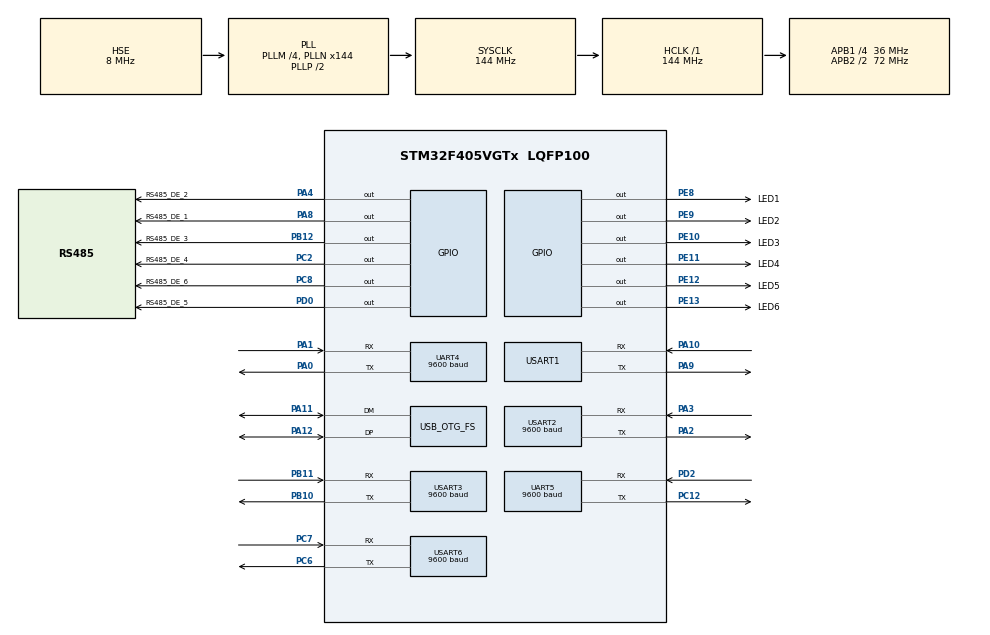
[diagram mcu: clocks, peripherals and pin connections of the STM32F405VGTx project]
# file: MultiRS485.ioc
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Dma.Request0=USART6_RX
Dma.Request1=USART3_RX
Dma.Request2=UART4_RX
Dma.Request3=UART5_RX
Dma.Request4=USART1_RX
Dma.UART4_RX.2.Direction=DMA_PERIPH_TO_MEMORY
Dma.UART4_RX.2.FIFOMode=DMA_FIFOMODE_DISABLE
Dma.UART4_RX.2.Instance=DMA1_Stream2
Dma.UART4_RX.2.MemDataAlignment=DMA_MDATAALIGN_BYTE
Dma.UART4_RX.2.MemInc=DMA_MINC_ENABLE
Dma.UART4_RX.2.Mode=DMA_NORMAL
Dma.UART4_RX.2.PeriphDataAlignment=DMA_PDATAALIGN_BYTE
Dma.UART4_RX.2.PeriphInc=DMA_PINC_DISABLE
Dma.UART4_RX.2.Priority=DMA_PRIORITY_LOW
Dma.UART5_RX.3.Direction=DMA_PERIPH_TO_MEMORY
Dma.UART5_RX.3.FIFOMode=DMA_FIFOMODE_DISABLE
Dma.UART5_RX.3.Instance=DMA1_Stream0
Dma.UART5_RX.3.MemDataAlignment=DMA_MDATAALIGN_BYTE
Dma.UART5_RX.3.MemInc=DMA_MINC_ENABLE
Dma.UART5_RX.3.Mode=DMA_NORMAL
Dma.UART5_RX.3.PeriphDataAlignment=DMA_PDATAALIGN_BYTE
Dma.UART5_RX.3.PeriphInc=DMA_PINC_DISABLE
Dma.UART5_RX.3.Priority=DMA_PRIORITY_LOW
Dma.USART1_RX.4.Direction=DMA_PERIPH_TO_MEMORY
Dma.USART1_RX.4.FIFOMode=DMA_FIFOMODE_DISABLE
Dma.USART1_RX.4.Instance=DMA2_Stream2
Dma.USART1_RX.4.MemDataAlignment=DMA_MDATAALIGN_BYTE
Dma.USART1_RX.4.MemInc=DMA_MINC_ENABLE
Dma.USART1_RX.4.Mode=DMA_NORMAL
Dma.USART1_RX.4.PeriphDataAlignment=DMA_PDATAALIGN_BYTE
Dma.USART1_RX.4.PeriphInc=DMA_PINC_DISABLE
Dma.USART1_RX.4.Priority=DMA_PRIORITY_LOW
Dma.USART3_RX.1.Direction=DMA_PERIPH_TO_MEMORY
Dma.USART3_RX.1.FIFOMode=DMA_FIFOMODE_DISABLE
Dma.USART3_RX.1.Instance=DMA1_Stream1
Dma.USART3_RX.1.MemDataAlignment=DMA_MDATAALIGN_BYTE
Dma.USART3_RX.1.MemInc=DMA_MINC_ENABLE
Dma.USART3_RX.1.Mode=DMA_NORMAL
Dma.USART3_RX.1.PeriphDataAlignment=DMA_PDATAALIGN_BYTE
Dma.USART3_RX.1.PeriphInc=DMA_PINC_DISABLE
Dma.USART3_RX.1.Priority=DMA_PRIORITY_LOW
Dma.USART6_RX.0.Direction=DMA_PERIPH_TO_MEMORY
Dma.USART6_RX.0.FIFOMode=DMA_FIFOMODE_DISABLE
Dma.USART6_RX.0.Instance=DMA2_Stream1
Dma.USART6_RX.0.MemDataAlignment=DMA_MDATAALIGN_BYTE
Dma.USART6_RX.0.MemInc=DMA_MINC_ENABLE
Dma.USART6_RX.0.Mode=DMA_NORMAL
Dma.USART6_RX.0.PeriphDataAlignment=DMA_PDATAALIGN_BYTE
Dma.USART6_RX.0.PeriphInc=DMA_PINC_DISABLE
Dma.USART6_RX.0.Priority=DMA_PRIORITY_LOW
FREERTOS.Tasks01=defaultTask,0,128,StartDefaultTask,Default,NULL
Mcu.Family=STM32F4
Mcu.Name=STM32F405VGTx
Mcu.Package=LQFP100
NVIC.DMA1_Stream0_IRQn=true\:5\:0\:false\:false\:true\:true\:false
NVIC.DMA1_Stream1_IRQn=true\:5\:0\:false\:false\:true\:true\:false
NVIC.DMA1_Stream2_IRQn=true\:5\:0\:false\:false\:true\:true\:false
NVIC.DMA2_Stream1_IRQn=true\:5\:0\:false\:false\:true\:true\:false
NVIC.DMA2_Stream2_IRQn=true\:5\:0\:false\:false\:true\:true\:false
NVIC.OTG_FS_IRQn=true\:5\:0\:false\:false\:true\:true\:false
NVIC.PriorityGroup=NVIC_PRIORITYGROUP_4
NVIC.TIM6_DAC_IRQn=true\:0\:0\:false\:false\:true\:false\:false
NVIC.TIM7_IRQn=true\:5\:0\:false\:false\:true\:true\:true
NVIC.TimeBase=TIM6_DAC_IRQn
NVIC.TimeBaseIP=TIM6
NVIC.UART4_IRQn=true\:5\:0\:false\:false\:true\:true\:true
NVIC.UART5_IRQn=true\:5\:0\:false\:false\:true\:true\:true
NVIC.USART1_IRQn=true\:5\:0\:false\:false\:true\:true\:true
NVIC.USART2_IRQn=true\:5\:0\:false\:false\:true\:true\:true
NVIC.USART3_IRQn=true\:5\:0\:false\:false\:true\:true\:true
NVIC.USART6_IRQn=true\:5\:0\:false\:false\:true\:true\:true
PA0-WKUP.Mode=Asynchronous
PA0-WKUP.Signal=UART4_TX
PA1.Mode=Asynchronous
PA1.Signal=UART4_RX
PA10.Mode=Asynchronous
PA10.Signal=USART1_RX
PA11.Mode=Device_Only
PA11.Signal=USB_OTG_FS_DM
PA12.Mode=Device_Only
PA12.Signal=USB_OTG_FS_DP
PA13.Mode=Serial_Wire
PA13.Signal=SYS_JTMS-SWDIO
PA14.Mode=Serial_Wire
PA14.Signal=SYS_JTCK-SWCLK
PA2.Mode=Asynchronous
PA2.Signal=USART2_TX
PA3.Mode=Asynchronous
PA3.Signal=USART2_RX
PA4.GPIO_Label=RS485_DE_2
PA4.GPIO_PuPd=GPIO_PULLDOWN
PA4.Signal=GPIO_Output
PA8.GPIO_Label=RS485_DE_1
PA8.GPIO_PuPd=GPIO_PULLDOWN
PA8.Signal=GPIO_Output
PA9.Mode=Asynchronous
PA9.Signal=USART1_TX
PB10.Mode=Asynchronous
PB10.Signal=USART3_TX
PB11.Mode=Asynchronous
PB11.Signal=USART3_RX
PB12.GPIO_Label=RS485_DE_3
PB12.GPIO_PuPd=GPIO_PULLDOWN
PB12.Signal=GPIO_Output
PC12.Mode=Asynchronous
PC12.Signal=UART5_TX
PC2.GPIO_Label=RS485_DE_4
PC2.GPIO_PuPd=GPIO_PULLDOWN
PC2.Signal=GPIO_Output
PC6.Mode=Asynchronous
PC6.Signal=USART6_TX
PC7.Mode=Asynchronous
PC7.Signal=USART6_RX
PC8.GPIO_Label=RS485_DE_6
PC8.GPIO_PuPd=GPIO_PULLDOWN
PC8.Signal=GPIO_Output
PD0.GPIO_Label=RS485_DE_5
PD0.Signal=GPIO_Output
PD2.Mode=Asynchronous
PD2.Signal=UART5_RX
PE10.GPIO_Label=LED3
PE10.GPIO_PuPd=GPIO_PULLUP
PE10.Signal=GPIO_Output
PE11.GPIO_Label=LED4
PE11.GPIO_PuPd=GPIO_PULLUP
PE11.Signal=GPIO_Output
PE12.GPIO_Label=LED5
PE12.GPIO_PuPd=GPIO_PULLUP
PE12.Signal=GPIO_Output
PE13.GPIO_Label=LED6
PE13.GPIO_PuPd=GPIO_PULLUP
PE13.Signal=GPIO_Output
PE8.GPIO_Label=LED1
PE8.GPIO_PuPd=GPIO_PULLUP
PE8.Signal=GPIO_Output
PE9.GPIO_Label=LED2
PE9.GPIO_PuPd=GPIO_PULLUP
PE9.Signal=GPIO_Output
PH0-OSC_IN.Mode=HSE-External-Oscillator
PH0-OSC_IN.Signal=RCC_OSC_IN
PH1-OSC_OUT.Mode=HSE-External-Oscillator
PH1-OSC_OUT.Signal=RCC_OSC_OUT
ProjectManager.HeapSize=0x200
ProjectManager.StackSize=0x400
ProjectManager.TargetToolchain=MDK-ARM V5
RCC.48MHZClocksFreq_Value=48000000
RCC.AHBFreq_Value=144000000
RCC.APB1CLKDivider=RCC_HCLK_DIV4
RCC.APB1Freq_Value=36000000
RCC.APB1TimFreq_Value=72000000
RCC.APB2CLKDivider=RCC_HCLK_DIV2
RCC.APB2Freq_Value=72000000
RCC.APB2TimFreq_Value=144000000
RCC.CortexFreq_Value=144000000
RCC.HCLKFreq_Value=144000000
RCC.HSE_VALUE=8000000
RCC.HSI_VALUE=16000000
RCC.LSE_VALUE=32768
RCC.PLLM=4
RCC.PLLN=144
RCC.PLLQ=6
RCC.SYSCLKFreq_VALUE=144000000
RCC.SYSCLKSource=RCC_SYSCLKSOURCE_PLLCLK
RCC.VCOOutputFreq_Value=288000000
TIM7.TIM_MasterOutputTrigger=TIM_TRGO_UPDATE
UART4.BaudRate=9600
UART4.VirtualMode=Asynchronous
UART5.BaudRate=9600
UART5.VirtualMode=Asynchronous
USART1.VirtualMode=VM_ASYNC
USART2.BaudRate=9600
USART2.VirtualMode=VM_ASYNC
USART3.BaudRate=9600
USART3.VirtualMode=VM_ASYNC
USART6.BaudRate=9600
USART6.VirtualMode=VM_ASYNC
USB_DEVICE.CLASS_NAME_FS=CDC
USB_DEVICE.VirtualMode-CDC_FS=Cdc
USB_DEVICE.VirtualModeFS=Cdc_FS
USB_OTG_FS.VirtualMode=Device_Only
VP_FREERTOS_VS_ENABLE.Mode=Enabled
VP_IWDG_VS_IWDG.Mode=IWDG_Activate
VP_SYS_VS_tim6.Mode=TIM6
VP_TIM7_VS_ClockSourceINT.Mode=Enable_Timer
VP_USB_DEVICE_VS_USB_DEVICE_CDC_FS.Mode=CDC_FS
board=custom

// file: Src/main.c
/**
  ******************************************************************************
  * @file           : main.c
  * @brief          : Main program body
  ******************************************************************************
  * This notice applies to any and all portions of this file
  * that are not between comment pairs USER CODE BEGIN and
  * USER CODE END. Other portions of this file, whether
  * inserted by the user or by software development tools
  * are owned by their respective copyright owners.
  *
  * Copyright (c) 2019 STMicroelectronics International N.V.
  * All rights reserved.
  *
  * Redistribution and use in source and binary forms, with or without
  * modification, are permitted, provided that the following conditions are met:
  *
  * 1. Redistribution of source code must retain the above copyright notice,
  *    this list of conditions and the following disclaimer.
  * 2. Redistributions in binary form must reproduce the above copyright notice,
  *    this list of conditions and the following disclaimer in the documentation
  *    and/or other materials provided with the distribution.
  * 3. Neither the name of STMicroelectronics nor the names of other
  *    contributors to this software may be used to endorse or promote products
  *    derived from this software without specific written permission.
  * 4. This software, including modifications and/or derivative works of this
  *    software, must execute solely and exclusively on microcontroller or
  *    microprocessor devices manufactured by or for STMicroelectronics.
  * 5. Redistribution and use of this software other than as permitted under
  *    this license is void and will automatically terminate your rights under
  *    this license.
  *
  * THIS SOFTWARE IS PROVIDED BY STMICROELECTRONICS AND CONTRIBUTORS "AS IS"
  * AND ANY EXPRESS, IMPLIED OR STATUTORY WARRANTIES, INCLUDING, BUT NOT
  * LIMITED TO, THE IMPLIED WARRANTIES OF MERCHANTABILITY, FITNESS FOR A
  * PARTICULAR PURPOSE AND NON-INFRINGEMENT OF THIRD PARTY INTELLECTUAL PROPERTY
  * RIGHTS ARE DISCLAIMED TO THE FULLEST EXTENT PERMITTED BY LAW. IN NO EVENT
  * SHALL STMICROELECTRONICS OR CONTRIBUTORS BE LIABLE FOR ANY DIRECT, INDIRECT,
  * INCIDENTAL, SPECIAL, EXEMPLARY, OR CONSEQUENTIAL DAMAGES (INCLUDING, BUT NOT
  * LIMITED TO, PROCUREMENT OF SUBSTITUTE GOODS OR SERVICES; LOSS OF USE, DATA,
  * OR PROFITS; OR BUSINESS INTERRUPTION) HOWEVER CAUSED AND ON ANY THEORY OF
  * LIABILITY, WHETHER IN CONTRACT, STRICT LIABILITY, OR TORT (INCLUDING
  * NEGLIGENCE OR OTHERWISE) ARISING IN ANY WAY OUT OF THE USE OF THIS SOFTWARE,
  * EVEN IF ADVISED OF THE POSSIBILITY OF SUCH DAMAGE.
  *
  ******************************************************************************
  */
#include "main.h"
#include "stm32f4xx_hal.h"
#include "cmsis_os.h"
#include "dma.h"
#include "iwdg.h"
#include "tim.h"
#include "usart.h"
#include "usb_device.h"
#include "gpio.h"

/* USER CODE BEGIN Includes */
#include "bsp_serial.h"
#include "bsp_rs485.h"
#include "mav_msg.h"
/* USER CODE END Includes */

/* USER CODE BEGIN PV */
/* Private variables ---------------------------------------------------------*/

/* USER CODE END PV */

void SystemClock_Config(void);
void MX_FREERTOS_Init(void);

/* USER CODE BEGIN PFP */
/* Private function prototypes -----------------------------------------------*/

/* USER CODE END PFP */

/* USER CODE BEGIN 0 */
char testbuf[] = {"hello world!\r\n"};
/* USER CODE END 0 */

int main(void)
{

  /* MCU Configuration----------------------------------------------------------*/

  /* Reset of all peripherals, Initializes the Flash interface and the Systick. */
  HAL_Init();

  /* Configure the system clock */
  SystemClock_Config();

  /* Initialize all configured peripherals */
  MX_GPIO_Init();
  MX_DMA_Init();
  MX_UART4_Init();
  MX_UART5_Init();
  MX_USART1_UART_Init();
  MX_USART2_UART_Init();
  MX_USART3_UART_Init();
  MX_USART6_UART_Init();
 // MX_IWDG_Init();
  MX_TIM7_Init();
  /* USER CODE BEGIN 2 */
	bsp_serial_config();
	rs485_config();
	RS485_printf("start...\r\n");
  /* USER CODE END 2 */

  /* Call init function for freertos objects (in freertos.c) */
  MX_FREERTOS_Init();

  /* Start scheduler */
  osKernelStart();

  /* We should never get here as control is now taken by the scheduler */

  /* Infinite loop */
  /* USER CODE BEGIN WHILE */
  //void mav_sendmsg(uint8_t com,uint8_t compid ,uint32_t msgid,uint8_t databuf[],uint8_t len)

  while (1)
  {
	 // mav_sendmsg(COM2,MAVLINK_COMP_ID_SYS,MAVLINK_MSG_ID_SYS_STATUS,(uint8_t*)testbuf,strlen((char*)testbuf));

	//  HAL_Delay(1000);
	  HAL_IWDG_Refresh(&hiwdg);
	  Mavlink_Msg_Handle();
	  RF_Msg_Handle();
  /* USER CODE END WHILE */

  }

}

void SystemClock_Config(void)
{

  RCC_OscInitTypeDef RCC_OscInitStruct;
  RCC_ClkInitTypeDef RCC_ClkInitStruct;

    /**Configure the main internal regulator output voltage
    */
  __HAL_RCC_PWR_CLK_ENABLE();

  __HAL_PWR_VOLTAGESCALING_CONFIG(PWR_REGULATOR_VOLTAGE_SCALE1);

    /**Initializes the CPU, AHB and APB busses clocks
    */
  RCC_OscInitStruct.OscillatorType = RCC_OSCILLATORTYPE_LSI|RCC_OSCILLATORTYPE_HSE;
  RCC_OscInitStruct.HSEState = RCC_HSE_ON;
  RCC_OscInitStruct.LSIState = RCC_LSI_ON;
  RCC_OscInitStruct.PLL.PLLState = RCC_PLL_ON;
  RCC_OscInitStruct.PLL.PLLSource = RCC_PLLSOURCE_HSE;
  RCC_OscInitStruct.PLL.PLLM = 4;
  RCC_OscInitStruct.PLL.PLLN = 144;
  RCC_OscInitStruct.PLL.PLLP = RCC_PLLP_DIV2;
  RCC_OscInitStruct.PLL.PLLQ = 6;
  if (HAL_RCC_OscConfig(&RCC_OscInitStruct) != HAL_OK)
  {
    _Error_Handler(__FILE__, __LINE__);
  }

    /**Initializes the CPU, AHB and APB busses clocks
    */
  RCC_ClkInitStruct.ClockType = RCC_CLOCKTYPE_HCLK|RCC_CLOCKTYPE_SYSCLK
                              |RCC_CLOCKTYPE_PCLK1|RCC_CLOCKTYPE_PCLK2;
  RCC_ClkInitStruct.SYSCLKSource = RCC_SYSCLKSOURCE_PLLCLK;
  RCC_ClkInitStruct.AHBCLKDivider = RCC_SYSCLK_DIV1;
  RCC_ClkInitStruct.APB1CLKDivider = RCC_HCLK_DIV4;
  RCC_ClkInitStruct.APB2CLKDivider = RCC_HCLK_DIV2;

  if (HAL_RCC_ClockConfig(&RCC_ClkInitStruct, FLASH_LATENCY_4) != HAL_OK)
  {
    _Error_Handler(__FILE__, __LINE__);
  }

    /**Configure the Systick interrupt time
    */
  HAL_SYSTICK_Config(HAL_RCC_GetHCLKFreq()/1000);

    /**Configure the Systick
    */
  HAL_SYSTICK_CLKSourceConfig(SYSTICK_CLKSOURCE_HCLK);

  /* SysTick_IRQn interrupt configuration */
  HAL_NVIC_SetPriority(SysTick_IRQn, 15, 0);
}

void HAL_TIM_PeriodElapsedCallback(TIM_HandleTypeDef *htim)
{
  if (htim->Instance == TIM6) {
    HAL_IncTick();
  }
}

void _Error_Handler(char *file, int line)
{
  while(1)
  {
  }
}

/************************ (C) COPYRIGHT STMicroelectronics *****END OF FILE****/

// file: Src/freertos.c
/**
  ******************************************************************************
  * File Name          : freertos.c
  * Description        : Code for freertos applications
  ******************************************************************************
  * This notice applies to any and all portions of this file
  * that are not between comment pairs USER CODE BEGIN and
  * USER CODE END. Other portions of this file, whether
  * inserted by the user or by software development tools
  * are owned by their respective copyright owners.
  *
  * Copyright (c) 2019 STMicroelectronics International N.V.
  * All rights reserved.
  *
  * Redistribution and use in source and binary forms, with or without
  * modification, are permitted, provided that the following conditions are met:
  *
  * 1. Redistribution of source code must retain the above copyright notice,
  *    this list of conditions and the following disclaimer.
  * 2. Redistributions in binary form must reproduce the above copyright notice,
  *    this list of conditions and the following disclaimer in the documentation
  *    and/or other materials provided with the distribution.
  * 3. Neither the name of STMicroelectronics nor the names of other
  *    contributors to this software may be used to endorse or promote products
  *    derived from this software without specific written permission.
  * 4. This software, including modifications and/or derivative works of this
  *    software, must execute solely and exclusively on microcontroller or
  *    microprocessor devices manufactured by or for STMicroelectronics.
  * 5. Redistribution and use of this software other than as permitted under
  *    this license is void and will automatically terminate your rights under
  *    this license.
  *
  * THIS SOFTWARE IS PROVIDED BY STMICROELECTRONICS AND CONTRIBUTORS "AS IS"
  * AND ANY EXPRESS, IMPLIED OR STATUTORY WARRANTIES, INCLUDING, BUT NOT
  * LIMITED TO, THE IMPLIED WARRANTIES OF MERCHANTABILITY, FITNESS FOR A
  * PARTICULAR PURPOSE AND NON-INFRINGEMENT OF THIRD PARTY INTELLECTUAL PROPERTY
  * RIGHTS ARE DISCLAIMED TO THE FULLEST EXTENT PERMITTED BY LAW. IN NO EVENT
  * SHALL STMICROELECTRONICS OR CONTRIBUTORS BE LIABLE FOR ANY DIRECT, INDIRECT,
  * INCIDENTAL, SPECIAL, EXEMPLARY, OR CONSEQUENTIAL DAMAGES (INCLUDING, BUT NOT
  * LIMITED TO, PROCUREMENT OF SUBSTITUTE GOODS OR SERVICES; LOSS OF USE, DATA,
  * OR PROFITS; OR BUSINESS INTERRUPTION) HOWEVER CAUSED AND ON ANY THEORY OF
  * LIABILITY, WHETHER IN CONTRACT, STRICT LIABILITY, OR TORT (INCLUDING
  * NEGLIGENCE OR OTHERWISE) ARISING IN ANY WAY OUT OF THE USE OF THIS SOFTWARE,
  * EVEN IF ADVISED OF THE POSSIBILITY OF SUCH DAMAGE.
  *
  ******************************************************************************
  */

#include "FreeRTOS.h"
#include "task.h"
#include "cmsis_os.h"

osThreadId defaultTaskHandle;

void StartDefaultTask(void const * argument);

extern void MX_USB_DEVICE_Init(void);
void MX_FREERTOS_Init(void); /* (MISRA C 2004 rule 8.1) */

/* USER CODE BEGIN FunctionPrototypes */
extern void ModbusRTUTask(void const * argument);

/* USER CODE END FunctionPrototypes */

/* Hook prototypes */

/* Init FreeRTOS */

void MX_FREERTOS_Init(void) {

  /* Create the thread(s) */
  /* definition and creation of defaultTask */
  osThreadDef(defaultTask, StartDefaultTask, osPriorityNormal, 0, 128);
  defaultTaskHandle = osThreadCreate(osThread(defaultTask), NULL);

  /* USER CODE BEGIN RTOS_THREADS */
  	osThreadDef(ModbusRTUTask, ModbusRTUTask, osPriorityNormal, 0, configMINIMAL_STACK_SIZE);
  osThreadCreate(osThread(ModbusRTUTask), NULL);

  /* add threads, ... */
  /* USER CODE END RTOS_THREADS */

}

/* StartDefaultTask function */
void StartDefaultTask(void const * argument)
{
  /* init code for USB_DEVICE */
  MX_USB_DEVICE_Init();

  for(;;)
  {
    osDelay(1);
  }
}

/************************ (C) COPYRIGHT STMicroelectronics *****END OF FILE****/
